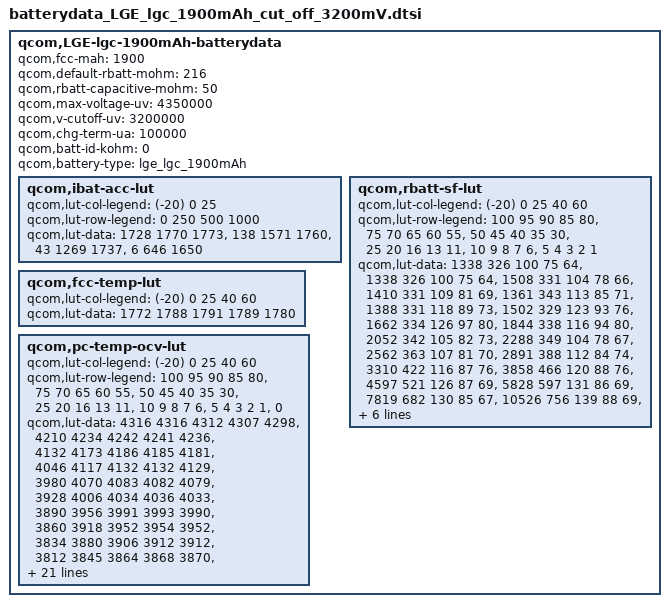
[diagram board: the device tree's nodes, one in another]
/* Copyright (c) 2014, The Linux Foundation. All rights reserved.
 *
 * This program is free software; you can redistribute it and/or modify
 * it under the terms of the GNU General Public License version 2 and
 * only version 2 as published by the Free Software Foundation.
 *
 * This program is distributed in the hope that it will be useful,
 * but WITHOUT ANY WARRANTY; without even the implied warranty of
 * MERCHANTABILITY or FITNESS FOR A PARTICULAR PURPOSE.  See the
 * GNU General Public License for more details.
 */
 qcom,LGE-lgc-1900mAh-batterydata {
	qcom,fcc-mah = <1900>;
	qcom,default-rbatt-mohm = <216>;
	qcom,rbatt-capacitive-mohm = <50>;
	qcom,max-voltage-uv = <4350000>;
	qcom,v-cutoff-uv = <3200000>;
	qcom,chg-term-ua = <100000>;
	qcom,batt-id-kohm = <0>;
        qcom,battery-type = "lge_lgc_1900mAh";

	qcom,ibat-acc-lut {
		qcom,lut-col-legend = <(-20) 0 25>;
		qcom,lut-row-legend = <0 250 500 1000>;
		qcom,lut-data = <1728 1770 1773>,
				<138 1571 1760>,
				<43 1269 1737>,
				<6 646 1650>;
	};

	qcom,rbatt-sf-lut {
		qcom,lut-col-legend = <(-20) 0 25 40 60>;
		qcom,lut-row-legend = <100 95 90 85 80>,
				<75 70 65 60 55>,
				<50 45 40 35 30>,
				<25 20 16 13 11>,
				<10 9 8 7 6>,
				<5 4 3 2 1>;
		qcom,lut-data = <1338 326 100 75 64>,
				<1338 326 100 75 64>,
				<1508 331 104 78 66>,
				<1410 331 109 81 69>,
				<1361 343 113 85 71>,
				<1388 331 118 89 73>,
				<1502 329 123 93 76>,
				<1662 334 126 97 80>,
				<1844 338 116 94 80>,
				<2052 342 105 82 73>,
				<2288 349 104 78 67>,
				<2562 363 107 81 70>,
				<2891 388 112 84 74>,
				<3310 422 116 87 76>,
				<3858 466 120 88 76>,
				<4597 521 126 87 69>,
				<5828 597 131 86 69>,
				<7819 682 130 85 67>,
				<10526 756 139 88 69>,
				<13375 809 149 92 73>,
				<14761 837 158 96 75>,
				<18019 865 168 100 76>,
				<21297 893 178 105 78>,
				<24575 906 184 106 79>,
				<29264 909 189 104 77>,
				<34430 855 176 100 75>,
				<39920 789 168 97 75>,
				<45465 868 178 103 79>,
				<53850 1060 197 113 88>,
				<66273 2120 269 159 103>;
	};

	qcom,fcc-temp-lut {
		qcom,lut-col-legend = <(-20) 0 25 40 60>;
		qcom,lut-data = <1772 1788 1791 1789 1780>;
	};

	qcom,pc-temp-ocv-lut {
		qcom,lut-col-legend = <(-20) 0 25 40 60>;
		qcom,lut-row-legend = <100 95 90 85 80>,
				<75 70 65 60 55>,
				<50 45 40 35 30>,
				<25 20 16 13 11>,
				<10 9 8 7 6>,
				<5 4 3 2 1>,
				<0>;
		qcom,lut-data = <4316 4316 4312 4307 4298>,
				<4210 4234 4242 4241 4236>,
				<4132 4173 4186 4185 4181>,
				<4046 4117 4132 4132 4129>,
				<3980 4070 4083 4082 4079>,
				<3928 4006 4034 4036 4033>,
				<3890 3956 3991 3993 3990>,
				<3860 3918 3952 3954 3952>,
				<3834 3880 3906 3912 3912>,
				<3812 3845 3864 3868 3870>,
				<3790 3814 3834 3835 3835>,
				<3770 3790 3810 3812 3812>,
				<3748 3774 3792 3794 3794>,
				<3724 3761 3778 3778 3778>,
				<3700 3750 3768 3765 3762>,
				<3668 3736 3756 3750 3738>,
				<3629 3720 3736 3728 3716>,
				<3582 3704 3703 3696 3684>,
				<3537 3691 3689 3683 3670>,
				<3499 3683 3682 3678 3666>,
				<3480 3677 3680 3676 3665>,
				<3449 3670 3676 3674 3662>,
				<3418 3664 3674 3672 3660>,
				<3387 3650 3665 3662 3655>,
				<3348 3632 3652 3646 3628>,
				<3307 3606 3624 3616 3602>,
				<3272 3562 3575 3566 3549>,
				<3226 3500 3509 3502 3484>,
				<3178 3410 3421 3414 3402>,
				<3126 3270 3282 3274 3270>,
				<3000 3000 3000 3000 3000>;
	};
};
